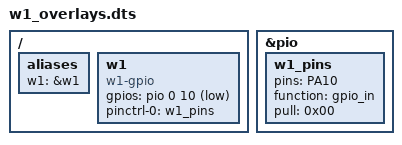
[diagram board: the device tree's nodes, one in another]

&pio {
	w1_pins: w1_pins {
		pins = "PA10";
		function = "gpio_in";
		pull = <0x00>;
	};
};

/ {
	aliases {
		w1 = &w1;
	};

	w1: w1 {
		compatible = "w1-gpio";
		gpios = <&pio 0 10 7>;
		pinctrl-names = "default";
		pinctrl-0 = <&w1_pins>;
		status = "okay";
	};
};

